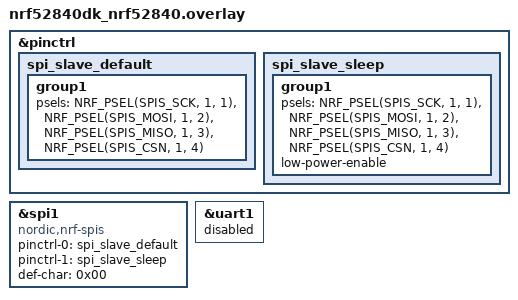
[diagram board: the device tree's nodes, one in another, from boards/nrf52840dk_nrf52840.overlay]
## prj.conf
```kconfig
CONFIG_GPIO=y
CONFIG_SPI=y
CONFIG_SPI_ASYNC=y
CONFIG_SPI_SLAVE=y
```

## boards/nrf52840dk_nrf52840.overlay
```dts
&pinctrl {
	spi_slave_default: spi_slave_default {
		group1 {
			psels = <NRF_PSEL(SPIS_SCK, 1, 1)>,
					<NRF_PSEL(SPIS_MOSI, 1, 2)>,
					<NRF_PSEL(SPIS_MISO, 1, 3)>,
					<NRF_PSEL(SPIS_CSN, 1, 4)>;
		};
	};

	spi_slave_sleep: spi_slave_sleep {
		group1 {
			psels = <NRF_PSEL(SPIS_SCK, 1, 1)>,
					<NRF_PSEL(SPIS_MOSI, 1, 2)>,
					<NRF_PSEL(SPIS_MISO, 1, 3)>,
					<NRF_PSEL(SPIS_CSN, 1, 4)>;
			low-power-enable;
		};
	};
};

my_spi_slave: &spi1 {
	compatible = "nordic,nrf-spis";
	status = "okay";
	pinctrl-0 = <&spi_slave_default>;
	pinctrl-1 = <&spi_slave_sleep>;
	pinctrl-names = "default", "sleep";
	def-char = <0x00>;
};

// By default uart1 will occupy P1.01 and P1.02. In order to make these pins available, disable uart1
&uart1 {
	status="disabled";
};
```

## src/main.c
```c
#include <zephyr/kernel.h>
#include <zephyr/device.h>
#include <zephyr/devicetree.h>
#include <zephyr/drivers/gpio.h>
#include <zephyr/drivers/spi.h>

/* 1000 msec = 1 sec */
#define SLEEP_TIME_MS   1000

/* The devicetree node identifier for the "led0" alias. */
#define LED0_NODE DT_ALIAS(led0)

#define MY_SPI_SLAVE  DT_NODELABEL(my_spi_slave)

const struct device *spi_dev;

// SPI slave functionality
const struct device *spi_slave_dev;

static const struct spi_config spi_slave_cfg = {
	.operation = SPI_WORD_SET(8) | SPI_TRANSFER_MSB |
				 SPI_MODE_CPOL | SPI_MODE_CPHA | SPI_OP_MODE_SLAVE,
	.frequency = 4000000,
	.slave = 0,
};

static uint8_t slave_tx_buffer[2];
static uint8_t slave_rx_buffer[2];
static int spi_slave_write_test_msg(void)
{
	static uint8_t counter = 0;


	const struct spi_buf s_tx_buf = {
		.buf = slave_tx_buffer,
		.len = sizeof(slave_tx_buffer)
	};
	const struct spi_buf_set s_tx = {
		.buffers = &s_tx_buf,
		.count = 1
	};

	struct spi_buf s_rx_buf = {
		.buf = slave_rx_buffer,
		.len = sizeof(slave_rx_buffer),
	};
	const struct spi_buf_set s_rx = {
		.buffers = &s_rx_buf,
		.count = 1
	};

	// Update the TX buffer with a rolling counter
	slave_tx_buffer[1] = counter++;
	printk("SPI slave TX: 0x%.2x, 0x%.2x\n", slave_tx_buffer[0], slave_tx_buffer[1]);

	// Start transaction
	int error = spi_transceive(spi_slave_dev, &spi_slave_cfg, &s_tx, &s_rx);
	if(error < 0){
		printk("SPI slave transceive error: %i\n", error);
		return error;
	}
	return 0;
}

/*
 * A build error on this line means your board is unsupported.
 * See the sample documentation for information on how to fix this.
 */
static const struct gpio_dt_spec led = GPIO_DT_SPEC_GET(LED0_NODE, gpios);

int main(void)
{
	int ret;

	if (!device_is_ready(led.port)) {
		return 0;
	}

	ret = gpio_pin_configure_dt(&led, GPIO_OUTPUT_ACTIVE);
	if (ret < 0) {
		return 0;
	}

	spi_slave_dev = DEVICE_DT_GET(MY_SPI_SLAVE);

	printk("SPI slave started\n");
	
	spi_slave_write_test_msg();

	while (1) {
		ret = gpio_pin_toggle_dt(&led);
		if (ret < 0) {
			return 0;
		}
		k_msleep(SLEEP_TIME_MS);

		// Print the last received data
		printk("SPI slave RX: 0x%.2x, 0x%.2x\n", slave_rx_buffer[0], slave_rx_buffer[1]);
		
		// Prepare the next SPI slave transaction	
		spi_slave_write_test_msg();
	}

	return 0;
}
```
